AUTOSAR XML (schema 4-0-3)
package /ComponentTypes
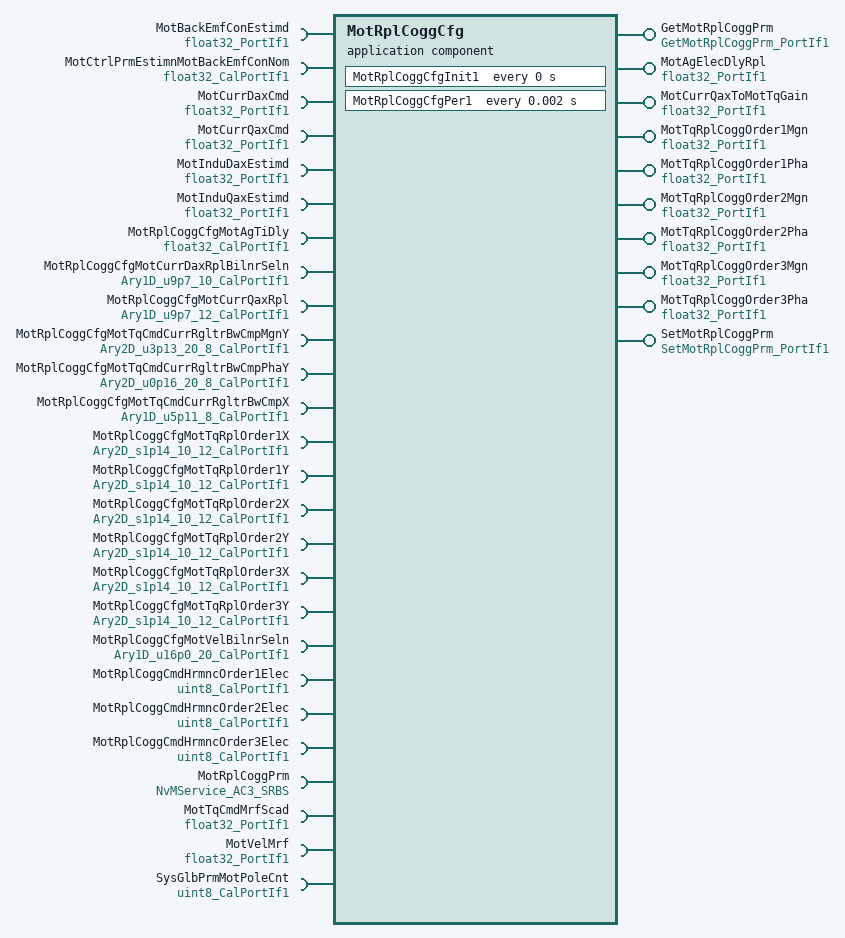
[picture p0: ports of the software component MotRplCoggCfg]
  application sw component type MotRplCoggCfg
    10 x provide port:
      GetMotRplCoggPrm: server-com-spec{operation=Oper, queue-length=1}, provided-interface=GetMotRplCoggPrm_PortIf1
      MotAgElecDlyRpl: nonqueued-sender-com-spec{data-element=Val, init-value=0}, provided-interface=float32_PortIf1
      MotCurrQaxToMotTqGain: nonqueued-sender-com-spec{data-element=Val, init-value=0.021651}, provided-interface=float32_PortIf1
      MotTqRplCoggOrder1Mgn: nonqueued-sender-com-spec{data-element=Val, init-value=0}, provided-interface=float32_PortIf1
      MotTqRplCoggOrder1Pha: nonqueued-sender-com-spec{data-element=Val, init-value=0}, provided-interface=float32_PortIf1
      MotTqRplCoggOrder2Mgn: nonqueued-sender-com-spec{data-element=Val, init-value=0}, provided-interface=float32_PortIf1
      MotTqRplCoggOrder2Pha: nonqueued-sender-com-spec{data-element=Val, init-value=0}, provided-interface=float32_PortIf1
      MotTqRplCoggOrder3Mgn: nonqueued-sender-com-spec{data-element=Val, init-value=0}, provided-interface=float32_PortIf1
      MotTqRplCoggOrder3Pha: nonqueued-sender-com-spec{data-element=Val, init-value=0}, provided-interface=float32_PortIf1
      SetMotRplCoggPrm: server-com-spec{operation=Oper, queue-length=1}, provided-interface=SetMotRplCoggPrm_PortIf1
    26 x require port:
      MotBackEmfConEstimd: nonqueued-receiver-com-spec{data-element=Val, filter=data-filter-type=ALWAYS, init-value=0.025}, required-interface=float32_PortIf1
      MotCtrlPrmEstimnMotBackEmfConNom: parameter-require-com-spec{init-value=0.04, parameter=Val}, required-interface=float32_CalPortIf1
      MotCurrDaxCmd: nonqueued-receiver-com-spec{data-element=Val, filter=data-filter-type=ALWAYS, init-value=0}, required-interface=float32_PortIf1
      MotCurrQaxCmd: nonqueued-receiver-com-spec{data-element=Val, filter=data-filter-type=ALWAYS, init-value=0}, required-interface=float32_PortIf1
      MotInduDaxEstimd: nonqueued-receiver-com-spec{data-element=Val, filter=data-filter-type=ALWAYS, init-value=0.00011889}, required-interface=float32_PortIf1
      MotInduQaxEstimd: nonqueued-receiver-com-spec{data-element=Val, filter=data-filter-type=ALWAYS, init-value=0.00011889}, required-interface=float32_PortIf1
      MotRplCoggCfgMotAgTiDly: parameter-require-com-spec{init-value=0, parameter=Val}, required-interface=float32_CalPortIf1
      MotRplCoggCfgMotCurrDaxRplBilnrSeln: parameter-require-com-spec{init-value=[0, 1280, 3200, 6400, 7680, 9600, 11520, 12800, 14080, 16000], parameter=Ary1D}, required-interface=Ary1D_u9p7_10_CalPortIf1
      MotRplCoggCfgMotCurrQaxRpl: parameter-require-com-spec{init-value=[0, 1280, 3200, 6400, 7680, 9600, 12800, 13440, 14080, 15360, 16000, 17280], parameter=Ary1D}, required-interface=Ary1D_u9p7_12_CalPortIf1
      MotRplCoggCfgMotTqCmdCurrRgltrBwCmpMgnY: parameter-require-com-spec{init-value=20 x 8 x 0, parameter=Ary2D}, required-interface=Ary2D_u3p13_20_8_CalPortIf1
      MotRplCoggCfgMotTqCmdCurrRgltrBwCmpPhaY: parameter-require-com-spec{init-value=20 x 8 x 0, parameter=Ary2D}, required-interface=Ary2D_u0p16_20_8_CalPortIf1
      MotRplCoggCfgMotTqCmdCurrRgltrBwCmpX: parameter-require-com-spec{init-value=[0, 1024, 2048, 4096, 6144, 8192, 9216, 10240], parameter=Ary1D}, required-interface=Ary1D_u5p11_8_CalPortIf1
      MotRplCoggCfgMotTqRplOrder1X: parameter-require-com-spec{init-value=10 x 12 x 0, parameter=Ary2D}, required-interface=Ary2D_s1p14_10_12_CalPortIf1
      MotRplCoggCfgMotTqRplOrder1Y: parameter-require-com-spec{init-value=10 x 12 x 0, parameter=Ary2D}, required-interface=Ary2D_s1p14_10_12_CalPortIf1
      MotRplCoggCfgMotTqRplOrder2X: parameter-require-com-spec{init-value=10 x 12 x 0, parameter=Ary2D}, required-interface=Ary2D_s1p14_10_12_CalPortIf1
      MotRplCoggCfgMotTqRplOrder2Y: parameter-require-com-spec{init-value=10 x 12 x 0, parameter=Ary2D}, required-interface=Ary2D_s1p14_10_12_CalPortIf1
      MotRplCoggCfgMotTqRplOrder3X: parameter-require-com-spec{init-value=10 x 12 x 0, parameter=Ary2D}, required-interface=Ary2D_s1p14_10_12_CalPortIf1
      MotRplCoggCfgMotTqRplOrder3Y: parameter-require-com-spec{init-value=10 x 12 x 0, parameter=Ary2D}, required-interface=Ary2D_s1p14_10_12_CalPortIf1
      MotRplCoggCfgMotVelBilnrSeln: parameter-require-com-spec{init-value=[0, 100, 114, 303, 800, 1200, 2600, 3200, 3700, 4200, 5000, 6000, 7200, 7500, 8000, 8500, 9000, 9500, 10000, 11000], parameter=Ary1D}, required-interface=Ary1D_u16p0_20_CalPortIf1
      MotRplCoggCmdHrmncOrder1Elec: parameter-require-com-spec{init-value=6, parameter=Val}, required-interface=uint8_CalPortIf1
      MotRplCoggCmdHrmncOrder2Elec: parameter-require-com-spec{init-value=12, parameter=Val}, required-interface=uint8_CalPortIf1
      MotRplCoggCmdHrmncOrder3Elec: parameter-require-com-spec{init-value=18, parameter=Val}, required-interface=uint8_CalPortIf1
      MotRplCoggPrm: required-com-specs=[EraseBlock, GetErrorStatus, InvalidateNvBlock, ReadBlock, SetRamBlockStatus, WriteBlock], required-interface=NvMService_AC3_SRBS
      MotTqCmdMrfScad: nonqueued-receiver-com-spec{data-element=Val, filter=data-filter-type=ALWAYS, init-value=0}, required-interface=float32_PortIf1
      MotVelMrf: nonqueued-receiver-com-spec{data-element=Val, filter=data-filter-type=ALWAYS, init-value=0}, required-interface=float32_PortIf1
      SysGlbPrmMotPoleCnt: parameter-require-com-spec{init-value=6, parameter=Val}, required-interface=uint8_CalPortIf1
    behavior MotRplCoggCfg_InternalBehavior
      ar-typed-per-instance-memorys:
        15 x data, all with sw-calibration-access=READ-ONLY:
          dMotRplCoggCfgMotAgElecDlyRpl: type=float32
          dMotRplCoggCfgMotCurrQaxToMotTqGain: type=float32
          dMotRplCoggCfgMotTqRplOrder1Mgn: type=float32
          dMotRplCoggCfgMotTqRplOrder1Pha: type=float32
          dMotRplCoggCfgMotTqRplOrder2Mgn: type=float32
          dMotRplCoggCfgMotTqRplOrder2Pha: type=float32
          dMotRplCoggCfgMotTqRplOrder3Mgn: type=float32
          dMotRplCoggCfgMotTqRplOrder3Pha: type=float32
          MotRplCoggPrm: type=MotRplCoggPrmRec2
          MotTqRplOrder1X: type=Ary2D_s1p14_10_12
          MotTqRplOrder1Y: type=Ary2D_s1p14_10_12
          MotTqRplOrder2X: type=Ary2D_s1p14_10_12
          MotTqRplOrder2Y: type=Ary2D_s1p14_10_12
          MotTqRplOrder3X: type=Ary2D_s1p14_10_12
          MotTqRplOrder3Y: type=Ary2D_s1p14_10_12
      operation invoked event OIT_GetMotRplCoggPrm_Oper_GetMotRplCoggPrm_Oper: start-on-event=GetMotRplCoggPrm_Oper, operation=GetMotRplCoggPrm.Oper
      timing event MotRplCoggCfgInit1_InitEvent: start-on-event=MotRplCoggCfgInit1, period=0
      timing event TMT_MotRplCoggCfgPer1: start-on-event=MotRplCoggCfgPer1, period=0.002
      operation invoked event OIT_SetMotRplCoggPrm_Oper_SetMotRplCoggPrm_Oper: start-on-event=SetMotRplCoggPrm_Oper, operation=SetMotRplCoggPrm.Oper
      4 x runnable:
        GetMotRplCoggPrm_Oper
        MotRplCoggCfgInit1
          sync call SC_MotRplCoggPrm_GetErrorStatus: operation=MotRplCoggPrm.GetErrorStatus, timeout=0
          sync call SC_MotRplCoggPrm_SetRamBlockStatus: operation=MotRplCoggPrm.SetRamBlockStatus, timeout=0
        MotRplCoggCfgPer1
          data-receive-point-by-arguments:
            7 x access:
              REC_MotBackEmfConEstimd_Val: accessed-variable=MotBackEmfConEstimd.Val
              REC_MotCurrDaxCmd_Val: accessed-variable=MotCurrDaxCmd.Val
              REC_MotCurrQaxCmd_Val: accessed-variable=MotCurrQaxCmd.Val
              REC_MotInduDaxEstimd_Val: accessed-variable=MotInduDaxEstimd.Val
              REC_MotInduQaxEstimd_Val: accessed-variable=MotInduQaxEstimd.Val
              REC_MotTqCmdMrfScad_Val: accessed-variable=MotTqCmdMrfScad.Val
              REC_MotVelMrf_Val: accessed-variable=MotVelMrf.Val
          data-send-points:
            8 x access:
              SEND_MotAgElecDlyRpl_Val: accessed-variable=MotAgElecDlyRpl.Val
              SEND_MotCurrQaxToMotTqGain_Val: accessed-variable=MotCurrQaxToMotTqGain.Val
              SEND_MotTqRplCoggOrder1Mgn_Val: accessed-variable=MotTqRplCoggOrder1Mgn.Val
              SEND_MotTqRplCoggOrder1Pha_Val: accessed-variable=MotTqRplCoggOrder1Pha.Val
              SEND_MotTqRplCoggOrder2Mgn_Val: accessed-variable=MotTqRplCoggOrder2Mgn.Val
              SEND_MotTqRplCoggOrder2Pha_Val: accessed-variable=MotTqRplCoggOrder2Pha.Val
              SEND_MotTqRplCoggOrder3Mgn_Val: accessed-variable=MotTqRplCoggOrder3Mgn.Val
              SEND_MotTqRplCoggOrder3Pha_Val: accessed-variable=MotTqRplCoggOrder3Pha.Val
        SetMotRplCoggPrm_Oper
          sync call SC_MotRplCoggPrm_SetRamBlockStatus: operation=MotRplCoggPrm.SetRamBlockStatus, timeout=0
      swc service dependency NvmMotRplCoggPrm: assigned-datas=role-based-data-assignment={role=ramBlock, used-data-element=MotRplCoggPrm}, assigned-ports=role-based-port-assignment={port-prototype=MotRplCoggPrm, role=NvMService_AC3_SRBS}
        service-needs:
          nv block needs NvmMotRplCoggPrm: n-data-sets=0, readonly=false, reliability=ERROR-DETECTION, resistant-to-changed-sw=true, restore-at-start=true, store-at-shutdown=true, write-only-once=false, writing-frequency=0, writing-priority=LOW
  swc implementation MotRplCoggCfg_Implementation: behavior=MotRplCoggCfg_InternalBehavior
    code-descriptors:
      code Default: artifact-descriptors=autosar-engineering-object={short-label=Default, category=SWSRC}
